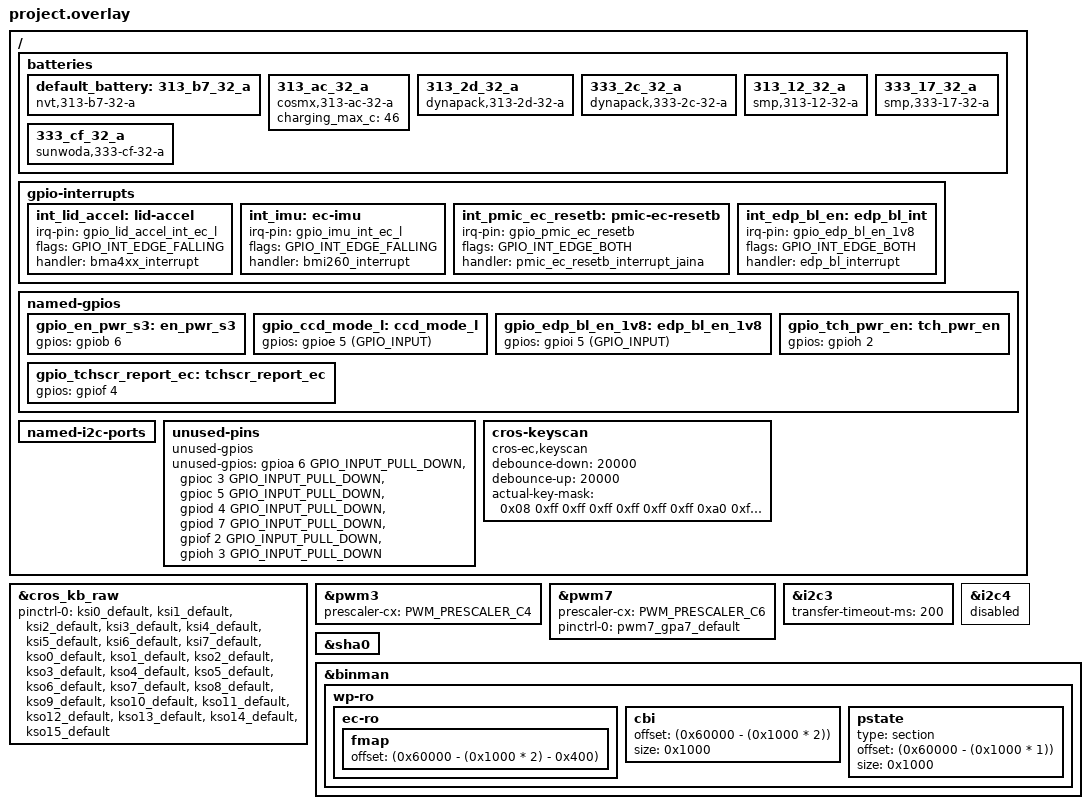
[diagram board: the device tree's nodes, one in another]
/* Copyright 2026 The ChromiumOS Authors
 * Use of this source code is governed by a BSD-style license that can be
 * found in the LICENSE file.
 */

#include <cros/cbi_flash.dtsi>
#include "../ite_generated.dtsi"
#include "../interrupts.dtsi"
#include "../ite_common.dtsi"
#include "../ite_keyboard.dtsi"
#include "../ite_overlay.dtsi"
#include "../ite_usbc.dtsi"
#include "../power_signal.dtsi"
#include "../usba.dtsi"
#include "led_pins.dtsi"
#include "temp_sensor.dtsi"
#include "cbi.dtsi"
#include "motionsense.dtsi"
#include "usbc.dtsi"

/ {
	batteries {
		default_battery: 313_b7_32_a {
			compatible = "nvt,313-b7-32-a", "battery-smart";
		};
		313_ac_32_a {
			compatible = "cosmx,313-ac-32-a", "battery-smart";
			charging_max_c = <46>;
		};
		313_2d_32_a {
			compatible = "dynapack,313-2d-32-a", "battery-smart";
		};
		333_2c_32_a {
			compatible = "dynapack,333-2c-32-a", "battery-smart";
		};
		313_12_32_a {
			compatible = "smp,313-12-32-a", "battery-smart";
		};
		333_17_32_a {
			compatible = "smp,333-17-32-a", "battery-smart";
		};
		333_cf_32_a {
			compatible = "sunwoda,333-cf-32-a", "battery-smart";
		};
	};

	gpio-interrupts {
		int_lid_accel: lid-accel {
			irq-pin = <&gpio_lid_accel_int_ec_l>;
			flags = <GPIO_INT_EDGE_FALLING>;
			handler = "bma4xx_interrupt";
		};
		int_imu: ec-imu {
			irq-pin = <&gpio_imu_int_ec_l>;
			flags = <GPIO_INT_EDGE_FALLING>;
			handler = "bmi260_interrupt";
		};
		int_pmic_ec_resetb: pmic-ec-resetb {
			irq-pin = <&gpio_pmic_ec_resetb>;
			flags = <GPIO_INT_EDGE_BOTH>;
			handler = "pmic_ec_resetb_interrupt_jaina";
		};
		int_edp_bl_en: edp_bl_int {
			irq-pin = <&gpio_edp_bl_en_1v8>;
			flags = <GPIO_INT_EDGE_BOTH>;
			handler = "edp_bl_interrupt";
		};
	};

	named-gpios {
		/delete-node/ ec_i2c_pdc1_sm_int_odl;
		/delete-node/ ec_i2c_pdc1_s_int_odl;
		/delete-node/ en_usb_c0_dev_mode;
		/delete-node/ ec_kso_02_inv;
		/delete-node/ en_pp5000_z1;
		/delete-node/ usb_c0_dp_hpd;
		/delete-node/ ec_i2c_pdc0_s_int_odl;

		gpio_en_pwr_s3: en_pwr_s3 {
			gpios = <&gpiob 6 (GPIO_OUTPUT | GPIO_ACTIVE_HIGH | GPIO_OUTPUT_INIT_LOW)>;
		};
		//CCD_MODE_L
		gpio_ccd_mode_l: ccd_mode_l {
			gpios = <&gpioe 5 (GPIO_INPUT)>;
		};
		gpio_edp_bl_en_1v8: edp_bl_en_1v8 {
			gpios = <&gpioi 5 (GPIO_INPUT)>;
		};
		gpio_tch_pwr_en: tch_pwr_en {
			gpios = <&gpioh 2 (GPIO_OUTPUT | GPIO_ACTIVE_HIGH | GPIO_OUTPUT_INIT_LOW)>;
		};
		gpio_tchscr_report_ec: tchscr_report_ec {
			gpios = <&gpiof 4 (GPIO_OUTPUT | GPIO_ACTIVE_HIGH | GPIO_OUTPUT_INIT_HIGH)>;
		};
	};

	named-i2c-ports {
		/delete-node/ ec_i2c_pdc_s_scl_3v3;
	};

	unused-pins {
		compatible = "unused-gpios";
		unused-gpios =
			<&gpioa 6 GPIO_INPUT_PULL_DOWN>,
			<&gpioc 3 GPIO_INPUT_PULL_DOWN>,
			<&gpioc 5 GPIO_INPUT_PULL_DOWN>,
			<&gpiod 4 GPIO_INPUT_PULL_DOWN>,
			<&gpiod 7 GPIO_INPUT_PULL_DOWN>,
			<&gpiof 2 GPIO_INPUT_PULL_DOWN>,
			<&gpioh 3 GPIO_INPUT_PULL_DOWN>;
	};

	cros-keyscan {
		compatible = "cros-ec,keyscan";

		debounce-down = <20000>;
		debounce-up = <20000>;

		actual-key-mask = <
			0x08	/* C0 */
			0xff	/* C1 */
			0xff	/* C2 */
			0xff	/* C3 */
			0xff	/* C4 */
			0xff	/* C5 */
			0xff	/* C6 */
			0xa0	/* C7 */
			0xff	/* C8 */
			0xff	/* C9 */
			0x54	/* C10 */
			0xff	/* C11 */
			0xff	/* C12 */
			0x41	/* C13 */
			0x0a	/* C14 */
			0x60	/* C15 */
		>;
	};
};

&cros_kb_raw {
	status = "okay";
	pinctrl-0 = <&ksi0_default
		     &ksi1_default
		     &ksi2_default
		     &ksi3_default
		     &ksi4_default
		     &ksi5_default
		     &ksi6_default
		     &ksi7_default
		     &kso0_default
		     &kso1_default
		     &kso2_default
		     &kso3_default
		     &kso4_default
		     &kso5_default
		     &kso6_default
		     &kso7_default
		     &kso8_default
		     &kso9_default
		     &kso10_default
		     &kso11_default
		     &kso12_default
		     &kso13_default
		     &kso14_default
		     &kso15_default>;
	pinctrl-names = "default";
};

&pwm3 {
	prescaler-cx = <PWM_PRESCALER_C4>;
};

&pwm7 {
	status = "okay";
	prescaler-cx = <PWM_PRESCALER_C6>;
	pinctrl-0 = <&pwm7_gpa7_default>;
	pinctrl-names = "default";
};

&i2c3 {
	transfer-timeout-ms = <200>;
};

&i2c4 {
	status = "disabled";
};

&sha0 {
	status = "okay";
};

/*
 * When CBI in flash is enabled, setup RO flash layout as follows:
 *   RO binary:    0x00000:0x5DFFF
 *   FMAP:         0x5DC00:0x5DFFF
 *   CBI flash:    0x5E000:0x5EFFF
 *   PSTATE block: 0x5F000:0x5FFFF
 */
&binman {
	wp-ro {
		/*
		 * Delete the pstate node so that we can force it to be the
		 * last sub-section. binman doesn't handle sub-sections with
		 * out of order offsets.
		 */
		 /delete-node/ pstate;

		 ec-ro {
			fmap {
				offset =  <(0x60000 - (0x1000 * 2) - 0x400)>;
				/*
				* don't specify 'size = <0x400>' here so
				* it is auto-assigned to the fmap size.
				*/
			};
		};
		cbi {
			offset = <(0x60000 - (0x1000 * 2))>;
			size = <0x1000>;
		};
		pstate {
			type = "section";
			offset = <(0x60000 - (0x1000 * 1))>;
			size = <0x1000>;
		};
	};
};
